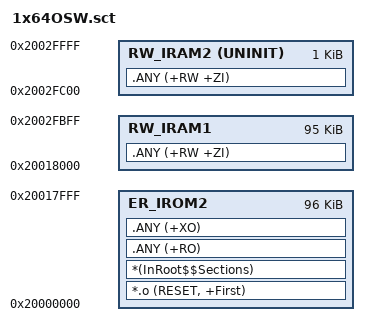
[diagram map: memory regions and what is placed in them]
; *************************************************************
; *** Scatter-Loading Description File generated by uVision ***
; *************************************************************

LR_IROM2 0x20000000 0x00018000  {    ; load region size_region
  ER_IROM2 0x20000000 0x00018000  {  ; load address = execution address
   *.o (RESET, +First)
   *(InRoot$$Sections)
   .ANY (+RO)
   .ANY (+XO)
  }
  RW_IRAM1 0x20018000 0x00017C00  {  ; RW data
   .ANY (+RW +ZI)
  }
  RW_IRAM2 0x2002FC00 UNINIT 0x00000400  {
   .ANY (+RW +ZI)
  }
}

